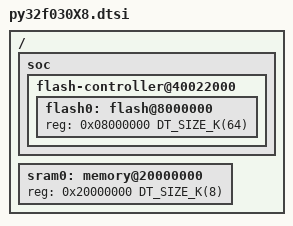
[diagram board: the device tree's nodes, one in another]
/*
 * SPDX-FileCopyrightText: Copyright The Zephyr Project Contributors
 * SPDX-License-Identifier: Apache-2.0
 */

#include <mem.h>
#include <puya/f0/py32f030.dtsi>

/ {
	soc {
		flash-controller@40022000 {
			flash0: flash@8000000 {
				reg = <0x08000000 DT_SIZE_K(64)>;
			};
		};
	};

	sram0: memory@20000000 {
		reg = <0x20000000 DT_SIZE_K(8)>;
	};
};
